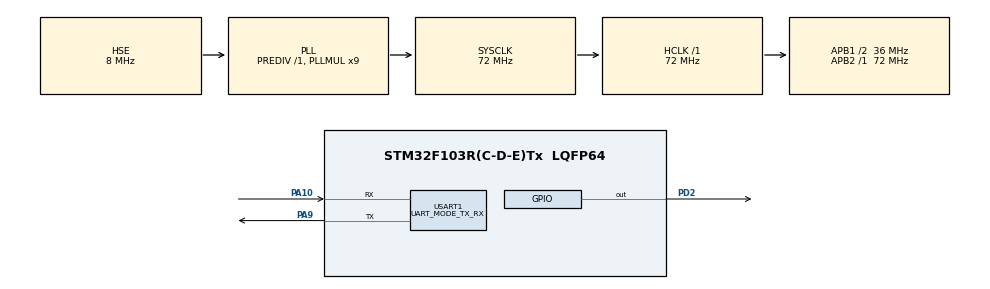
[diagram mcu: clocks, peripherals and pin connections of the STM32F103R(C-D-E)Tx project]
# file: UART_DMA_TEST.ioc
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Dma.Request0=USART1_RX
Dma.Request1=USART1_TX
Dma.USART1_RX.0.Direction=DMA_PERIPH_TO_MEMORY
Dma.USART1_RX.0.Instance=DMA1_Channel5
Dma.USART1_RX.0.MemDataAlignment=DMA_MDATAALIGN_BYTE
Dma.USART1_RX.0.MemInc=DMA_MINC_ENABLE
Dma.USART1_RX.0.Mode=DMA_NORMAL
Dma.USART1_RX.0.PeriphDataAlignment=DMA_PDATAALIGN_BYTE
Dma.USART1_RX.0.PeriphInc=DMA_PINC_DISABLE
Dma.USART1_RX.0.Priority=DMA_PRIORITY_HIGH
Dma.USART1_TX.1.Direction=DMA_MEMORY_TO_PERIPH
Dma.USART1_TX.1.Instance=DMA1_Channel4
Dma.USART1_TX.1.MemDataAlignment=DMA_MDATAALIGN_BYTE
Dma.USART1_TX.1.MemInc=DMA_MINC_ENABLE
Dma.USART1_TX.1.Mode=DMA_NORMAL
Dma.USART1_TX.1.PeriphDataAlignment=DMA_PDATAALIGN_BYTE
Dma.USART1_TX.1.PeriphInc=DMA_PINC_DISABLE
Dma.USART1_TX.1.Priority=DMA_PRIORITY_HIGH
Mcu.Family=STM32F1
Mcu.Name=STM32F103R(C-D-E)Tx
Mcu.Package=LQFP64
NVIC.DMA1_Channel4_IRQn=true\:1\:1\:true\:false\:true
NVIC.DMA1_Channel5_IRQn=true\:1\:1\:true\:false\:true
NVIC.PriorityGroup=NVIC_PRIORITYGROUP_2
PA10.Mode=Asynchronous
PA10.Signal=USART1_RX
PA13.Mode=Serial_Wire
PA13.Signal=SYS_JTMS-SWDIO
PA14.Mode=Serial_Wire
PA14.Signal=SYS_JTCK-SWCLK
PA9.Mode=Asynchronous
PA9.Signal=USART1_TX
PD0-OSC_IN.Mode=HSE-External-Oscillator
PD0-OSC_IN.Signal=RCC_OSC_IN
PD1-OSC_OUT.Mode=HSE-External-Oscillator
PD1-OSC_OUT.Signal=RCC_OSC_OUT
PD2.GPIO_Speed=GPIO_SPEED_FREQ_HIGH
PD2.PinState=GPIO_PIN_SET
PD2.Signal=GPIO_Output
ProjectManager.HeapSize=0x200
ProjectManager.StackSize=0x400
ProjectManager.TargetToolchain=MDK-ARM V5
RCC.AHBFreq_Value=72000000
RCC.APB1CLKDivider=RCC_HCLK_DIV2
RCC.APB1Freq_Value=36000000
RCC.APB1TimFreq_Value=72000000
RCC.APB2Freq_Value=72000000
RCC.APB2TimFreq_Value=72000000
RCC.HCLKFreq_Value=72000000
RCC.HSIState=RCC_HSI_ON
RCC.PLLMUL=RCC_PLL_MUL9
RCC.PLLSourceVirtual=RCC_PLLSOURCE_HSE
RCC.SYSCLKFreq_VALUE=72000000
RCC.SYSCLKSource=RCC_SYSCLKSOURCE_PLLCLK
RCC.USBFreq_Value=72000000
USART1.Mode=UART_MODE_TX_RX
board=UART_DMA_TEST

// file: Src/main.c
/**
  ******************************************************************************
  * File Name          : main.c
  * Description        : Main program body
  ******************************************************************************
  *
  * COPYRIGHT(c) 2016 STMicroelectronics
  *
  * Redistribution and use in source and binary forms, with or without modification,
  * are permitted provided that the following conditions are met:
  *   1. Redistributions of source code must retain the above copyright notice,
  *      this list of conditions and the following disclaimer.
  *   2. Redistributions in binary form must reproduce the above copyright notice,
  *      this list of conditions and the following disclaimer in the documentation
  *      and/or other materials provided with the distribution.
  *   3. Neither the name of STMicroelectronics nor the names of its contributors
  *      may be used to endorse or promote products derived from this software
  *      without specific prior written permission.
  *
  * THIS SOFTWARE IS PROVIDED BY THE COPYRIGHT HOLDERS AND CONTRIBUTORS "AS IS"
  * AND ANY EXPRESS OR IMPLIED WARRANTIES, INCLUDING, BUT NOT LIMITED TO, THE
  * IMPLIED WARRANTIES OF MERCHANTABILITY AND FITNESS FOR A PARTICULAR PURPOSE ARE
  * DISCLAIMED. IN NO EVENT SHALL THE COPYRIGHT HOLDER OR CONTRIBUTORS BE LIABLE
  * FOR ANY DIRECT, INDIRECT, INCIDENTAL, SPECIAL, EXEMPLARY, OR CONSEQUENTIAL
  * DAMAGES (INCLUDING, BUT NOT LIMITED TO, PROCUREMENT OF SUBSTITUTE GOODS OR
  * SERVICES; LOSS OF USE, DATA, OR PROFITS; OR BUSINESS INTERRUPTION) HOWEVER
  * CAUSED AND ON ANY THEORY OF LIABILITY, WHETHER IN CONTRACT, STRICT LIABILITY,
  * OR TORT (INCLUDING NEGLIGENCE OR OTHERWISE) ARISING IN ANY WAY OUT OF THE USE
  * OF THIS SOFTWARE, EVEN IF ADVISED OF THE POSSIBILITY OF SUCH DAMAGE.
  *
  ******************************************************************************
  */
#include "main.h"
#include "stm32f1xx_hal.h"
#include "dma.h"
#include "usart.h"
#include "gpio.h"

/* USER CODE BEGIN Includes */
#include "delay.h"

/* USER CODE END Includes */

/* USER CODE BEGIN PV */
/* Private variables ---------------------------------------------------------*/
static uint8_t transData[5] = {0x0F, 0XEA, 0X31, 0x0D, 0x0A};

/* USER CODE END PV */

void SystemClock_Config(void);
void Error_Handler(void);

/* USER CODE BEGIN PFP */
/* Private function prototypes -----------------------------------------------*/

/* USER CODE END PFP */

int main(void)
{

  /* MCU Configuration----------------------------------------------------------*/

  /* Reset of all peripherals, Initializes the Flash interface and the Systick. */
  HAL_Init();

  /* Configure the system clock */
  SystemClock_Config();

  /* Initialize all configured peripherals */
  MX_GPIO_Init();
  MX_DMA_Init();
  MX_USART1_UART_Init();

  /* Infinite loop */
  while (1)
  {
		HAL_UART_Transmit_DMA(&huart1, transData, 5);
		HAL_UART_Receive_DMA(&huart1, transData, 5);
		DelayMS(100);
  }

}

/** System Clock Configuration
*/
void SystemClock_Config(void)
{

  RCC_OscInitTypeDef RCC_OscInitStruct;
  RCC_ClkInitTypeDef RCC_ClkInitStruct;

    /**Initializes the CPU, AHB and APB busses clocks
    */
  RCC_OscInitStruct.OscillatorType = RCC_OSCILLATORTYPE_HSE;
  RCC_OscInitStruct.HSEState = RCC_HSE_ON;
  RCC_OscInitStruct.HSEPredivValue = RCC_HSE_PREDIV_DIV1;
  RCC_OscInitStruct.HSIState = RCC_HSI_ON;
  RCC_OscInitStruct.PLL.PLLState = RCC_PLL_ON;
  RCC_OscInitStruct.PLL.PLLSource = RCC_PLLSOURCE_HSE;
  RCC_OscInitStruct.PLL.PLLMUL = RCC_PLL_MUL9;
  if (HAL_RCC_OscConfig(&RCC_OscInitStruct) != HAL_OK)
  {
    Error_Handler();
  }

    /**Initializes the CPU, AHB and APB busses clocks
    */
  RCC_ClkInitStruct.ClockType = RCC_CLOCKTYPE_HCLK|RCC_CLOCKTYPE_SYSCLK
                              |RCC_CLOCKTYPE_PCLK1|RCC_CLOCKTYPE_PCLK2;
  RCC_ClkInitStruct.SYSCLKSource = RCC_SYSCLKSOURCE_PLLCLK;
  RCC_ClkInitStruct.AHBCLKDivider = RCC_SYSCLK_DIV1;
  RCC_ClkInitStruct.APB1CLKDivider = RCC_HCLK_DIV2;
  RCC_ClkInitStruct.APB2CLKDivider = RCC_HCLK_DIV1;

  if (HAL_RCC_ClockConfig(&RCC_ClkInitStruct, FLASH_LATENCY_2) != HAL_OK)
  {
    Error_Handler();
  }

    /**Configure the Systick interrupt time
    */
  HAL_SYSTICK_Config(HAL_RCC_GetHCLKFreq()/1000);

    /**Configure the Systick
    */
  HAL_SYSTICK_CLKSourceConfig(SYSTICK_CLKSOURCE_HCLK);

  /* SysTick_IRQn interrupt configuration */
  HAL_NVIC_SetPriority(SysTick_IRQn, 0, 1);
}

void Error_Handler(void)
{
  while(1)
  {
  }
}

/************************ (C) COPYRIGHT STMicroelectronics *****END OF FILE****/
